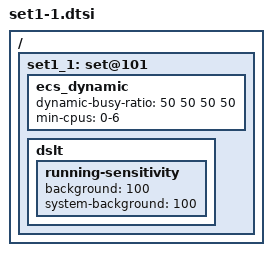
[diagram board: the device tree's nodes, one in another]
/ {
	/* power-scenario mode - touch boost */
	set1_1: set@101 {

		ecs_dynamic {
			dynamic-busy-ratio = <50 50 50 50>;
			min-cpus = "0-6";
		};

		dslt {
			running-sensitivity {
				background = <100>;
				system-background = <100>;
			};
		};
	};
};
